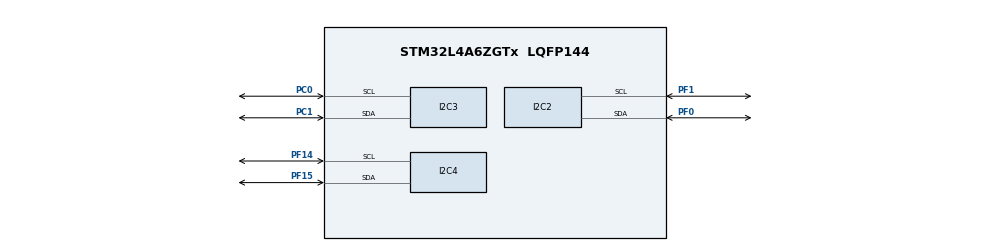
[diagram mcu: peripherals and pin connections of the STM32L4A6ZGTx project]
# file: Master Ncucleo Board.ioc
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Mcu.Family=STM32L4
Mcu.Name=STM32L4A6ZGTx
Mcu.Package=LQFP144
NVIC.I2C2_ER_IRQn=true\:0\:0\:false\:false\:true\:true\:true
NVIC.I2C2_EV_IRQn=true\:0\:0\:false\:false\:true\:true\:true
NVIC.I2C3_ER_IRQn=true\:0\:0\:false\:false\:true\:true\:true
NVIC.I2C3_EV_IRQn=true\:0\:0\:false\:false\:true\:true\:true
NVIC.I2C4_ER_IRQn=true\:0\:0\:false\:false\:true\:true\:true
NVIC.I2C4_EV_IRQn=true\:0\:0\:false\:false\:true\:true\:true
NVIC.PriorityGroup=NVIC_PRIORITYGROUP_4
PC0.GPIO_PuPdOD=GPIO_NOPULL
PC0.Mode=I2C
PC0.Signal=I2C3_SCL
PC1.GPIO_PuPdOD=GPIO_NOPULL
PC1.Mode=I2C
PC1.Signal=I2C3_SDA
PF0.GPIO_PuPdOD=GPIO_NOPULL
PF0.Mode=I2C
PF0.Signal=I2C2_SDA
PF1.GPIO_PuPdOD=GPIO_NOPULL
PF1.Mode=I2C
PF1.Signal=I2C2_SCL
PF14.GPIO_PuPdOD=GPIO_NOPULL
PF14.Mode=I2C
PF14.Signal=I2C4_SCL
PF15.GPIO_PuPdOD=GPIO_NOPULL
PF15.Mode=I2C
PF15.Signal=I2C4_SDA
ProjectManager.HeapSize=0x200
ProjectManager.StackSize=0x400
ProjectManager.TargetToolchain=EWARM V8.32
RCC.HSE_VALUE=8000000
RCC.HSI48_VALUE=48000000
RCC.HSI_VALUE=16000000
RCC.LSE_VALUE=32768
RCC.MSI_VALUE=4000000
RCC.VCOOutputFreq_Value=32000000
board=custom

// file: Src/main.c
/* USER CODE BEGIN Header */
/**
  ******************************************************************************
  * @file           : main.c
  * @brief          : Main program body
  ******************************************************************************
  * @attention
  *
  * <h2><center>&copy; Copyright (c) 2019 STMicroelectronics.
  * All rights reserved.</center></h2>
  *
  * This software component is licensed by ST under BSD 3-Clause license,
  * the "License"; You may not use this file except in compliance with the
  * License. You may obtain a copy of the License at:
  *                        opensource.org/licenses/BSD-3-Clause
  *
  ******************************************************************************
  */
/* USER CODE END Header */

#include "main.h"
#include "stdio.h"

/* USER CODE BEGIN PD */
#define MASTER_BOARD
#define I2C_ADDRESS        0x01
/* USER CODE END PD */

I2C_HandleTypeDef hi2c2;
I2C_HandleTypeDef hi2c3;
I2C_HandleTypeDef hi2c4;

/* USER CODE BEGIN PV */

/* Buffer used for transmission */
uint8_t aTxBuffer[] = " Hello from Master Board ! ";

/* Buffer used for reception */
uint8_t aRxBuffer[RXBUFFERSIZE];

/* USER CODE END PV */

void SystemClock_Config(void);
static void MX_GPIO_Init(void);
static void MX_I2C2_Init(void);
static void MX_I2C3_Init(void);
static void MX_I2C4_Init(void);

static void Error_Handler(void);

int main(void)
{

  /* MCU Configuration--------------------------------------------------------*/

  /* Reset of all peripherals, Initializes the Flash interface and the Systick. */
  HAL_Init();

  /* Configure the system clock */
  SystemClock_Config();

  /* USER CODE BEGIN SysInit */
    /* Configure LED1 and LED3 */

  /* USER CODE END SysInit */

  /* Initialize all configured peripherals */
  MX_GPIO_Init();
  MX_I2C2_Init();
  MX_I2C3_Init();
  MX_I2C4_Init();

  /* Infinite loop */
  while (1)
  {
    if (HAL_I2C_Master_Transmit_IT(&hi2c3, (uint16_t)I2C_ADDRESS, (uint8_t *)aTxBuffer, TXBUFFERSIZE) == HAL_OK)
    {
      HAL_Delay(3000);
    }
    while (HAL_I2C_GetState(&hi2c3) != HAL_I2C_STATE_READY)
    {
      HAL_Delay(1000);
    }

  }
}

void SystemClock_Config(void)
{
  RCC_OscInitTypeDef RCC_OscInitStruct = {0};
  RCC_ClkInitTypeDef RCC_ClkInitStruct = {0};
  RCC_PeriphCLKInitTypeDef PeriphClkInit = {0};

  /** Initializes the CPU, AHB and APB busses clocks
  */
  RCC_OscInitStruct.OscillatorType = RCC_OSCILLATORTYPE_MSI;
  RCC_OscInitStruct.MSIState = RCC_MSI_ON;
  RCC_OscInitStruct.MSICalibrationValue = 0;
  RCC_OscInitStruct.MSIClockRange = RCC_MSIRANGE_6;
  RCC_OscInitStruct.PLL.PLLState = RCC_PLL_NONE;
  if (HAL_RCC_OscConfig(&RCC_OscInitStruct) != HAL_OK)
  {
    Error_Handler();
  }
  /** Initializes the CPU, AHB and APB busses clocks
  */
  RCC_ClkInitStruct.ClockType = RCC_CLOCKTYPE_HCLK|RCC_CLOCKTYPE_SYSCLK
                              |RCC_CLOCKTYPE_PCLK1|RCC_CLOCKTYPE_PCLK2;
  RCC_ClkInitStruct.SYSCLKSource = RCC_SYSCLKSOURCE_MSI;
  RCC_ClkInitStruct.AHBCLKDivider = RCC_SYSCLK_DIV1;
  RCC_ClkInitStruct.APB1CLKDivider = RCC_HCLK_DIV1;
  RCC_ClkInitStruct.APB2CLKDivider = RCC_HCLK_DIV1;

  if (HAL_RCC_ClockConfig(&RCC_ClkInitStruct, FLASH_LATENCY_0) != HAL_OK)
  {
    Error_Handler();
  }
  PeriphClkInit.PeriphClockSelection = RCC_PERIPHCLK_I2C2|RCC_PERIPHCLK_I2C3
                              |RCC_PERIPHCLK_I2C4;
  PeriphClkInit.I2c2ClockSelection = RCC_I2C2CLKSOURCE_PCLK1;
  PeriphClkInit.I2c3ClockSelection = RCC_I2C3CLKSOURCE_PCLK1;
  PeriphClkInit.I2c4ClockSelection = RCC_I2C4CLKSOURCE_PCLK1;
  if (HAL_RCCEx_PeriphCLKConfig(&PeriphClkInit) != HAL_OK)
  {
    Error_Handler();
  }
  /** Configure the main internal regulator output voltage
  */
  if (HAL_PWREx_ControlVoltageScaling(PWR_REGULATOR_VOLTAGE_SCALE1) != HAL_OK)
  {
    Error_Handler();
  }
}

static void MX_I2C2_Init(void)
{

  hi2c2.Instance = I2C2;
  hi2c2.Init.Timing = 0x00000E14;
  hi2c2.Init.OwnAddress1 = 0x01;
  hi2c2.Init.AddressingMode = I2C_ADDRESSINGMODE_7BIT;
  hi2c2.Init.DualAddressMode = I2C_DUALADDRESS_DISABLE;
  hi2c2.Init.OwnAddress2 = 0;
  hi2c2.Init.OwnAddress2Masks = I2C_OA2_NOMASK;
  hi2c2.Init.GeneralCallMode = I2C_GENERALCALL_DISABLE;
  hi2c2.Init.NoStretchMode = I2C_NOSTRETCH_DISABLE;
  if (HAL_I2C_Init(&hi2c2) != HAL_OK)
  {
    Error_Handler();
  }
  /** Configure Analogue filter
  */
  if (HAL_I2CEx_ConfigAnalogFilter(&hi2c2, I2C_ANALOGFILTER_ENABLE) != HAL_OK)
  {
    Error_Handler();
  }
  /** Configure Digital filter
  */
  if (HAL_I2CEx_ConfigDigitalFilter(&hi2c2, 0) != HAL_OK)
  {
    Error_Handler();
  }

}

static void MX_I2C3_Init(void)
{

  hi2c3.Instance = I2C3;
  hi2c3.Init.Timing = 0x00000E14;
  hi2c3.Init.OwnAddress1 = 0x01;
  hi2c3.Init.AddressingMode = I2C_ADDRESSINGMODE_7BIT;
  hi2c3.Init.DualAddressMode = I2C_DUALADDRESS_DISABLE;
  hi2c3.Init.OwnAddress2 = 0;
  hi2c3.Init.OwnAddress2Masks = I2C_OA2_NOMASK;
  hi2c3.Init.GeneralCallMode = I2C_GENERALCALL_DISABLE;
  hi2c3.Init.NoStretchMode = I2C_NOSTRETCH_DISABLE;
  if (HAL_I2C_Init(&hi2c3) != HAL_OK)
  {
    Error_Handler();
  }
  /** Configure Analogue filter
  */
  if (HAL_I2CEx_ConfigAnalogFilter(&hi2c3, I2C_ANALOGFILTER_ENABLE) != HAL_OK)
  {
    Error_Handler();
  }
  /** Configure Digital filter
  */
  if (HAL_I2CEx_ConfigDigitalFilter(&hi2c3, 0) != HAL_OK)
  {
    Error_Handler();
  }

}

static void MX_I2C4_Init(void)
{

  hi2c4.Instance = I2C4;
  hi2c4.Init.Timing = 0x00000E14;
  hi2c4.Init.OwnAddress1 = 0x01;
  hi2c4.Init.AddressingMode = I2C_ADDRESSINGMODE_7BIT;
  hi2c4.Init.DualAddressMode = I2C_DUALADDRESS_DISABLE;
  hi2c4.Init.OwnAddress2 = 0;
  hi2c4.Init.OwnAddress2Masks = I2C_OA2_NOMASK;
  hi2c4.Init.GeneralCallMode = I2C_GENERALCALL_DISABLE;
  hi2c4.Init.NoStretchMode = I2C_NOSTRETCH_DISABLE;
  if (HAL_I2C_Init(&hi2c4) != HAL_OK)
  {
    Error_Handler();
  }
  /** Configure Analogue filter
  */
  if (HAL_I2CEx_ConfigAnalogFilter(&hi2c4, I2C_ANALOGFILTER_ENABLE) != HAL_OK)
  {
    Error_Handler();
  }
  /** Configure Digital filter
  */
  if (HAL_I2CEx_ConfigDigitalFilter(&hi2c4, 0) != HAL_OK)
  {
    Error_Handler();
  }

}

static void MX_GPIO_Init(void)
{

  /* GPIO Ports Clock Enable */
  __HAL_RCC_GPIOF_CLK_ENABLE();
  __HAL_RCC_GPIOC_CLK_ENABLE();

}

/* USER CODE BEGIN 4 */

void HAL_I2C_MasterTxCpltCallback(I2C_HandleTypeDef *hi2c1)
{
  /* Toggle LED1: Transfer in transmission process is correct */
  printf("Transfer correct from callback !! \n ");
}

/**
  * @brief  I2C error callbacks.
  * @param  hi2c1: I2C handle
  * @note   This example shows a simple way to report transfer error, and you can
  *         add your own implementation.
  * @retval None
  */
void HAL_I2C_ErrorCallback(I2C_HandleTypeDef *hi2c1)
{
  /** Error_Handler() function is called when error occurs.
    * 1- When Slave don't acknowledge it's address, Master restarts communication.
    * 2- When Master don't acknowledge the last data transferred, Slave don't care in this example.
    */
  if (HAL_I2C_GetError(hi2c1) != HAL_I2C_ERROR_AF)
  {
    /* Turn Off LED1 */
  printf("Error while transmission");

  }
}

/**
  * @brief  This function is executed in case of error occurrence.
  * @param  None
  * @retval None
  */
static void Error_Handler(void)
{
    /* Turn LED3 on */
  printf("Error while transmission LED3");
    while(1)
    {
    }
}

/* USER CODE END 4 */

/************************ (C) COPYRIGHT STMicroelectronics *****END OF FILE****/
